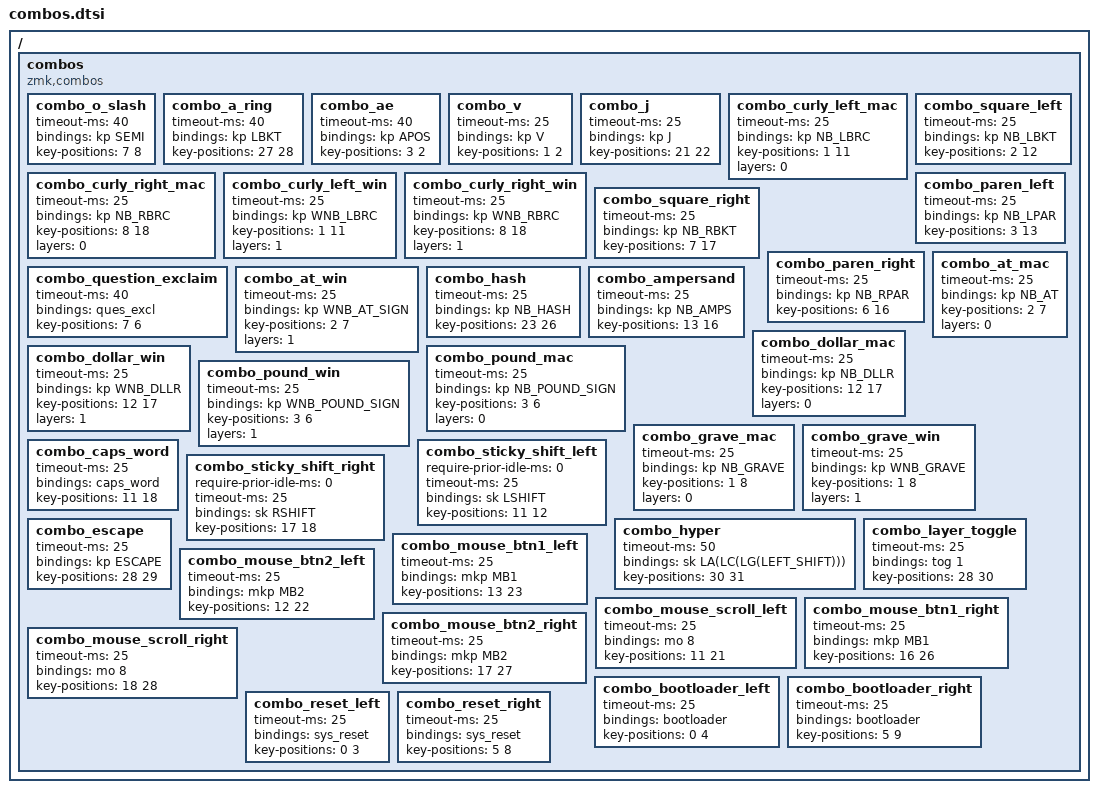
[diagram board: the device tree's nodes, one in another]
/ {
    combos {
        compatible = "zmk,combos";

        // ============================================
        // LETTERS & SPECIAL CHARACTERS
        // ============================================

        // Norwegian vowels
        combo_o_slash {                    // ø
            timeout-ms = <40>;
            bindings = <&kp SEMI>;
            key-positions = <7 8>;
        };

        combo_a_ring {                     // å
            timeout-ms = <40>;
            bindings = <&kp LBKT>;
            key-positions = <27 28>;
        };

        combo_ae {                         // æ
            timeout-ms = <40>;
            bindings = <&kp APOS>;
            key-positions = <3 2>;
        };
        combo_v {                          // v
            timeout-ms = <25>;
            bindings = <&kp V>;
            key-positions = <1 2>;
        };

        combo_j {                          // j
            timeout-ms = <25>;
            bindings = <&kp J>;
            key-positions = <21 22>;
        };

        // ============================================
        // BRACKETS & BRACES
        // ============================================

        // Curly braces { }
        combo_curly_left_mac {             // {
            timeout-ms = <25>;
            bindings = <&kp NB_LBRC>;
            key-positions = <1 11>;
            layers = <0>;
        };

        combo_curly_right_mac {            // }
            timeout-ms = <25>;
            bindings = <&kp NB_RBRC>;
            key-positions = <8 18>;
            layers = <0>;
        };

        combo_curly_left_win {             // {
            timeout-ms = <25>;
            bindings = <&kp WNB_LBRC>;
            key-positions = <1 11>;
            layers = <1>;
        };

        combo_curly_right_win {            // }
            timeout-ms = <25>;
            bindings = <&kp WNB_RBRC>;
            key-positions = <8 18>;
            layers = <1>;
        };

        // Square brackets [ ]
        combo_square_left {                // [
            timeout-ms = <25>;
            bindings = <&kp NB_LBKT>;
            key-positions = <2 12>;
        };

        combo_square_right {               // ]
            timeout-ms = <25>;
            bindings = <&kp NB_RBKT>;
            key-positions = <7 17>;
        };

        // Parentheses ( )
        combo_paren_left {                 // (
            timeout-ms = <25>;
            bindings = <&kp NB_LPAR>;
            key-positions = <3 13>;
        };

        combo_paren_right {                // )
            timeout-ms = <25>;
            bindings = <&kp NB_RPAR>;
            key-positions = <6 16>;
        };

        // ============================================
        // PUNCTUATION & SYMBOLS
        // ============================================

        combo_question_exclaim {           // ?!
            timeout-ms = <40>;
            bindings = <&ques_excl>;
            key-positions = <7 6>;
        };

        combo_at_mac {                     // @
            timeout-ms = <25>;
            bindings = <&kp NB_AT>;
            key-positions = <2 7>;
            layers = <0>;
        };

        combo_at_win {                     // @
            timeout-ms = <25>;
            bindings = <&kp WNB_AT_SIGN>;
            key-positions = <2 7>;
            layers = <1>;
        };

        combo_hash {                       // #
            timeout-ms = <25>;
            bindings = <&kp NB_HASH>;
            key-positions = <23 26>;
        };

        combo_ampersand {                  // &
            timeout-ms = <25>;
            bindings = <&kp NB_AMPS>;
            key-positions = <13 16>;
        };

        combo_dollar_mac {                 // $
            timeout-ms = <25>;
            bindings = <&kp NB_DLLR>;
            key-positions = <12 17>;
            layers = <0>;
        };

        combo_dollar_win {                 // $
            timeout-ms = <25>;
            bindings = <&kp WNB_DLLR>;
            key-positions = <12 17>;
            layers = <1>;
        };

        combo_pound_mac {                  // £
            timeout-ms = <25>;
            bindings = <&kp NB_POUND_SIGN>;
            key-positions = <3 6>;
            layers = <0>;
        };

        combo_pound_win {                  // £
            timeout-ms = <25>;
            bindings = <&kp WNB_POUND_SIGN>;
            key-positions = <3 6>;
            layers = <1>;
        };

        combo_grave_mac {                  // `
            timeout-ms = <25>;
            bindings = <&kp NB_GRAVE>;
            key-positions = <1 8>;
            layers = <0>;
        };

        combo_grave_win {                  // `
            timeout-ms = <25>;
            bindings = <&kp WNB_GRAVE>;
            key-positions = <1 8>;
            layers = <1>;
        };

        // ============================================
        // MODIFIERS
        // ============================================

        combo_caps_word {                  // Caps Word
            timeout-ms = <25>;
            bindings = <&caps_word>;
            key-positions = <11 18>;
        };

        combo_sticky_shift_left {          // Sticky Shift
            require-prior-idle-ms = <0>;
            timeout-ms = <25>;
            bindings = <&sk LSHIFT>;
            key-positions = <11 12>;
        };

        combo_sticky_shift_right {         // Sticky Shift
            require-prior-idle-ms = <0>;
            timeout-ms = <25>;
            bindings = <&sk RSHIFT>;
            key-positions = <17 18>;
        };

        // ============================================
        // THUMB COMBOS
        // ============================================

        combo_escape {                     // ESC
            timeout-ms = <25>;
            bindings = <&kp ESCAPE>;
            key-positions = <28 29>;
        };

        combo_hyper {                      // Hyper (⌃⌥⌘⇧)
            timeout-ms = <50>;
            bindings = <&sk LA(LC(LG(LEFT_SHIFT)))>;
            key-positions = <30 31>;
        };

        combo_layer_toggle {               // Toggle Windows layer
            timeout-ms = <25>;
            bindings = <&tog 1>;
            key-positions = <28 30>;
        };

        // ============================================
        // MOUSE CONTROLS
        // ============================================

        combo_mouse_btn1_left {            // Left Click
            timeout-ms = <25>;
            bindings = <&mkp MB1>;
            key-positions = <13 23>;
        };

        combo_mouse_btn2_left {            // Right Click
            timeout-ms = <25>;
            bindings = <&mkp MB2>;
            key-positions = <12 22>;
        };

        combo_mouse_scroll_left {          // Scroll Layer
            timeout-ms = <25>;
            bindings = <&mo 8>;
            key-positions = <11 21>;
        };

        combo_mouse_btn1_right {           // Left Click
            timeout-ms = <25>;
            bindings = <&mkp MB1>;
            key-positions = <16 26>;
        };

        combo_mouse_btn2_right {           // Right Click
            timeout-ms = <25>;
            bindings = <&mkp MB2>;
            key-positions = <17 27>;
        };

        combo_mouse_scroll_right {         // Scroll Layer
            timeout-ms = <25>;
            bindings = <&mo 8>;
            key-positions = <18 28>;
        };

        // ============================================
        // SYSTEM FUNCTIONS
        // ============================================

        combo_bootloader_left {            // Bootloader
            timeout-ms = <25>;
            bindings = <&bootloader>;
            key-positions = <0 4>;
        };

        combo_bootloader_right {           // Bootloader
            timeout-ms = <25>;
            bindings = <&bootloader>;
            key-positions = <5 9>;
        };

        combo_reset_left {                 // Reset
            timeout-ms = <25>;
            bindings = <&sys_reset>;
            key-positions = <0 3>;
        };

        combo_reset_right {                // Reset
            timeout-ms = <25>;
            bindings = <&sys_reset>;
            key-positions = <5 8>;
        };
    };
};
